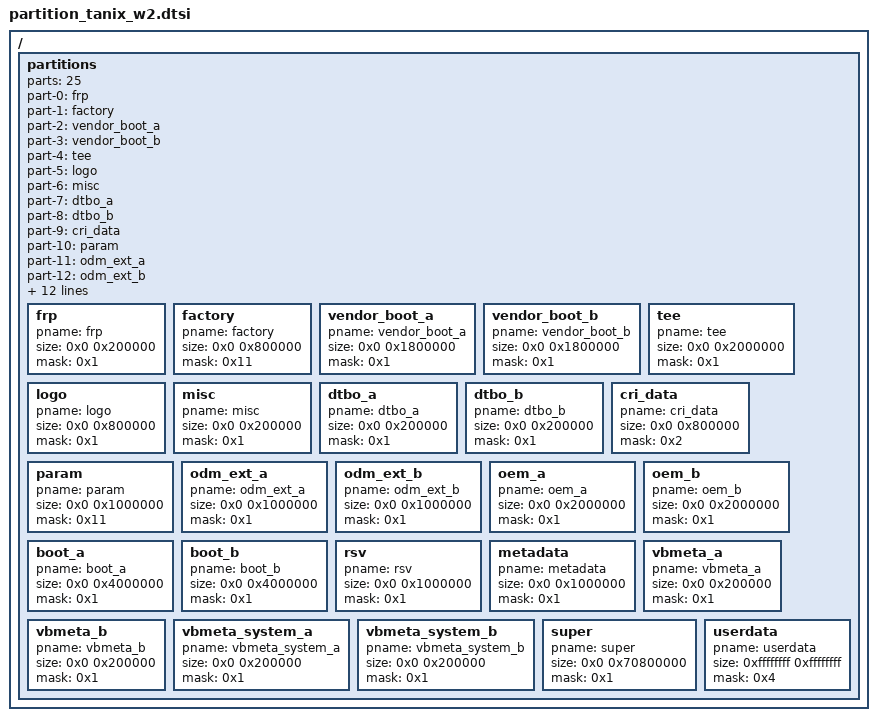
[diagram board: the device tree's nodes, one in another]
// SPDX-License-Identifier: (GPL-2.0+ OR MIT)
/*
 * Tanix W2 eMMC partition table.
 *
 * Generated from the stock S905W2-20260506 firmware DTB (s4_s905w2_2g) by
 * resolving /partitions part-N phandles. Index order, names, sizes and masks
 * MUST stay byte-identical to stock: Amlogic U-Boot derives the eMMC layout
 * from this table. Differs from partition_mbox_ab.dtsi (super size, param mask).
 */

#include "firmware_ab.dtsi"

/ {
	partitions: partitions {
		parts = <25>;
		part-0 = <&frp>;
		part-1 = <&factory>;
		part-2 = <&vendor_boot_a>;
		part-3 = <&vendor_boot_b>;
		part-4 = <&tee>;
		part-5 = <&logo>;
		part-6 = <&misc>;
		part-7 = <&dtbo_a>;
		part-8 = <&dtbo_b>;
		part-9 = <&cri_data>;
		part-10 = <&param>;
		part-11 = <&odm_ext_a>;
		part-12 = <&odm_ext_b>;
		part-13 = <&oem_a>;
		part-14 = <&oem_b>;
		part-15 = <&boot_a>;
		part-16 = <&boot_b>;
		part-17 = <&rsv>;
		part-18 = <&metadata>;
		part-19 = <&vbmeta_a>;
		part-20 = <&vbmeta_b>;
		part-21 = <&vbmeta_system_a>;
		part-22 = <&vbmeta_system_b>;
		part-23 = <&super>;
		part-24 = <&userdata>;

		frp: frp {
			pname = "frp";
			size = <0x0 0x200000>;
			mask = <0x1>;
		};
		factory: factory {
			pname = "factory";
			size = <0x0 0x800000>;
			mask = <0x11>;
		};
		vendor_boot_a: vendor_boot_a {
			pname = "vendor_boot_a";
			size = <0x0 0x1800000>;
			mask = <0x1>;
		};
		vendor_boot_b: vendor_boot_b {
			pname = "vendor_boot_b";
			size = <0x0 0x1800000>;
			mask = <0x1>;
		};
		tee: tee {
			pname = "tee";
			size = <0x0 0x2000000>;
			mask = <0x1>;
		};
		logo: logo {
			pname = "logo";
			size = <0x0 0x800000>;
			mask = <0x1>;
		};
		misc: misc {
			pname = "misc";
			size = <0x0 0x200000>;
			mask = <0x1>;
		};
		dtbo_a: dtbo_a {
			pname = "dtbo_a";
			size = <0x0 0x200000>;
			mask = <0x1>;
		};
		dtbo_b: dtbo_b {
			pname = "dtbo_b";
			size = <0x0 0x200000>;
			mask = <0x1>;
		};
		cri_data: cri_data {
			pname = "cri_data";
			size = <0x0 0x800000>;
			mask = <0x2>;
		};
		param: param {
			pname = "param";
			size = <0x0 0x1000000>;
			mask = <0x11>;
		};
		odm_ext_a: odm_ext_a {
			pname = "odm_ext_a";
			size = <0x0 0x1000000>;
			mask = <0x1>;
		};
		odm_ext_b: odm_ext_b {
			pname = "odm_ext_b";
			size = <0x0 0x1000000>;
			mask = <0x1>;
		};
		oem_a: oem_a {
			pname = "oem_a";
			size = <0x0 0x2000000>;
			mask = <0x1>;
		};
		oem_b: oem_b {
			pname = "oem_b";
			size = <0x0 0x2000000>;
			mask = <0x1>;
		};
		boot_a: boot_a {
			pname = "boot_a";
			size = <0x0 0x4000000>;
			mask = <0x1>;
		};
		boot_b: boot_b {
			pname = "boot_b";
			size = <0x0 0x4000000>;
			mask = <0x1>;
		};
		rsv: rsv {
			pname = "rsv";
			size = <0x0 0x1000000>;
			mask = <0x1>;
		};
		metadata: metadata {
			pname = "metadata";
			size = <0x0 0x1000000>;
			mask = <0x1>;
		};
		vbmeta_a: vbmeta_a {
			pname = "vbmeta_a";
			size = <0x0 0x200000>;
			mask = <0x1>;
		};
		vbmeta_b: vbmeta_b {
			pname = "vbmeta_b";
			size = <0x0 0x200000>;
			mask = <0x1>;
		};
		vbmeta_system_a: vbmeta_system_a {
			pname = "vbmeta_system_a";
			size = <0x0 0x200000>;
			mask = <0x1>;
		};
		vbmeta_system_b: vbmeta_system_b {
			pname = "vbmeta_system_b";
			size = <0x0 0x200000>;
			mask = <0x1>;
		};
		super: super {
			pname = "super";
			size = <0x0 0x70800000>;
			mask = <0x1>;
		};
		userdata: userdata {
			pname = "userdata";
			size = <0xffffffff 0xffffffff>;
			mask = <0x4>;
		};
	};
};
